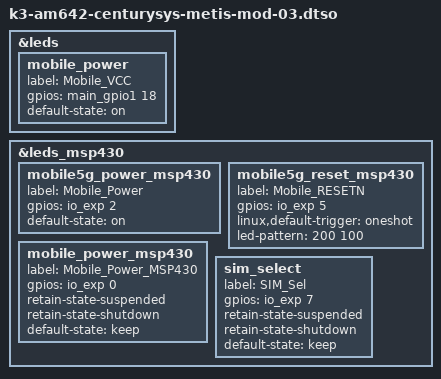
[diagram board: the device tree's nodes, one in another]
// SPDX-License-Identifier: GPL-2.0
/**
 * DT overlay for LTE/5G module (Module Code: 0x03)
 *
 * Copyright (C) 2023 Century Systems
 */

/dts-v1/;
/plugin/;
#include <dt-bindings/gpio/gpio.h>
#include <dt-bindings/interrupt-controller/irq.h>
#include "k3-pinctrl.h"

&leds {
	mobile_power {
		label = "Mobile_VCC";
		gpios = <&main_gpio1 18 GPIO_ACTIVE_HIGH>;
		default-state = "on";
	};
};

&leds_msp430 {
	mobile5g_power_msp430 {
		label = "Mobile_Power";
		gpios = <&io_exp 2 GPIO_ACTIVE_HIGH>;
		default-state = "on";
	};

	mobile5g_reset_msp430 {
		label = "Mobile_RESETN";
		gpios = <&io_exp 5 GPIO_ACTIVE_HIGH>;
		linux,default-trigger = "oneshot";
		led-pattern = <200 100>;
	};

	mobile_power_msp430 {
		label = "Mobile_Power_MSP430";
		gpios = <&io_exp 0 GPIO_ACTIVE_HIGH>;
		retain-state-suspended;
		retain-state-shutdown;
		default-state = "keep";
	};

	sim_select {
		label = "SIM_Sel";
		gpios = <&io_exp 7 GPIO_ACTIVE_HIGH>;
		retain-state-suspended;
		retain-state-shutdown;
		default-state = "keep";
	};
};
